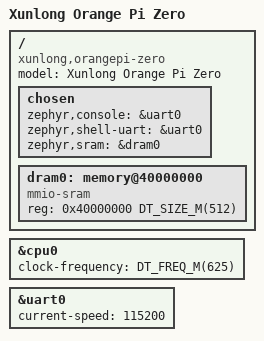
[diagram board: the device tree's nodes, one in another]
/*
 * Copyright (c) 2025 Muhammad Waleed Badar
 *
 * SPDX-License-Identifier: Apache-2.0
 */

/dts-v1/;

#include <allwinner/sun8i-h3.dtsi>

/ {
	model = "Xunlong Orange Pi Zero";
	compatible = "xunlong,orangepi-zero", "allwinner,sun8i-h2-plus";
	#address-cells = <1>;
	#size-cells = <1>;

	chosen {
		zephyr,console = &uart0;
		zephyr,shell-uart = &uart0;
		zephyr,sram = &dram0;
	};

	dram0: memory@40000000 {
		device_type = "memory";
		compatible = "mmio-sram";
		reg = <0x40000000 DT_SIZE_M(512)>;
	};
};

&cpu0 {
	clock-frequency = <DT_FREQ_M(625)>;
};

&uart0 {
	status = "okay";
	current-speed = <115200>;
};
